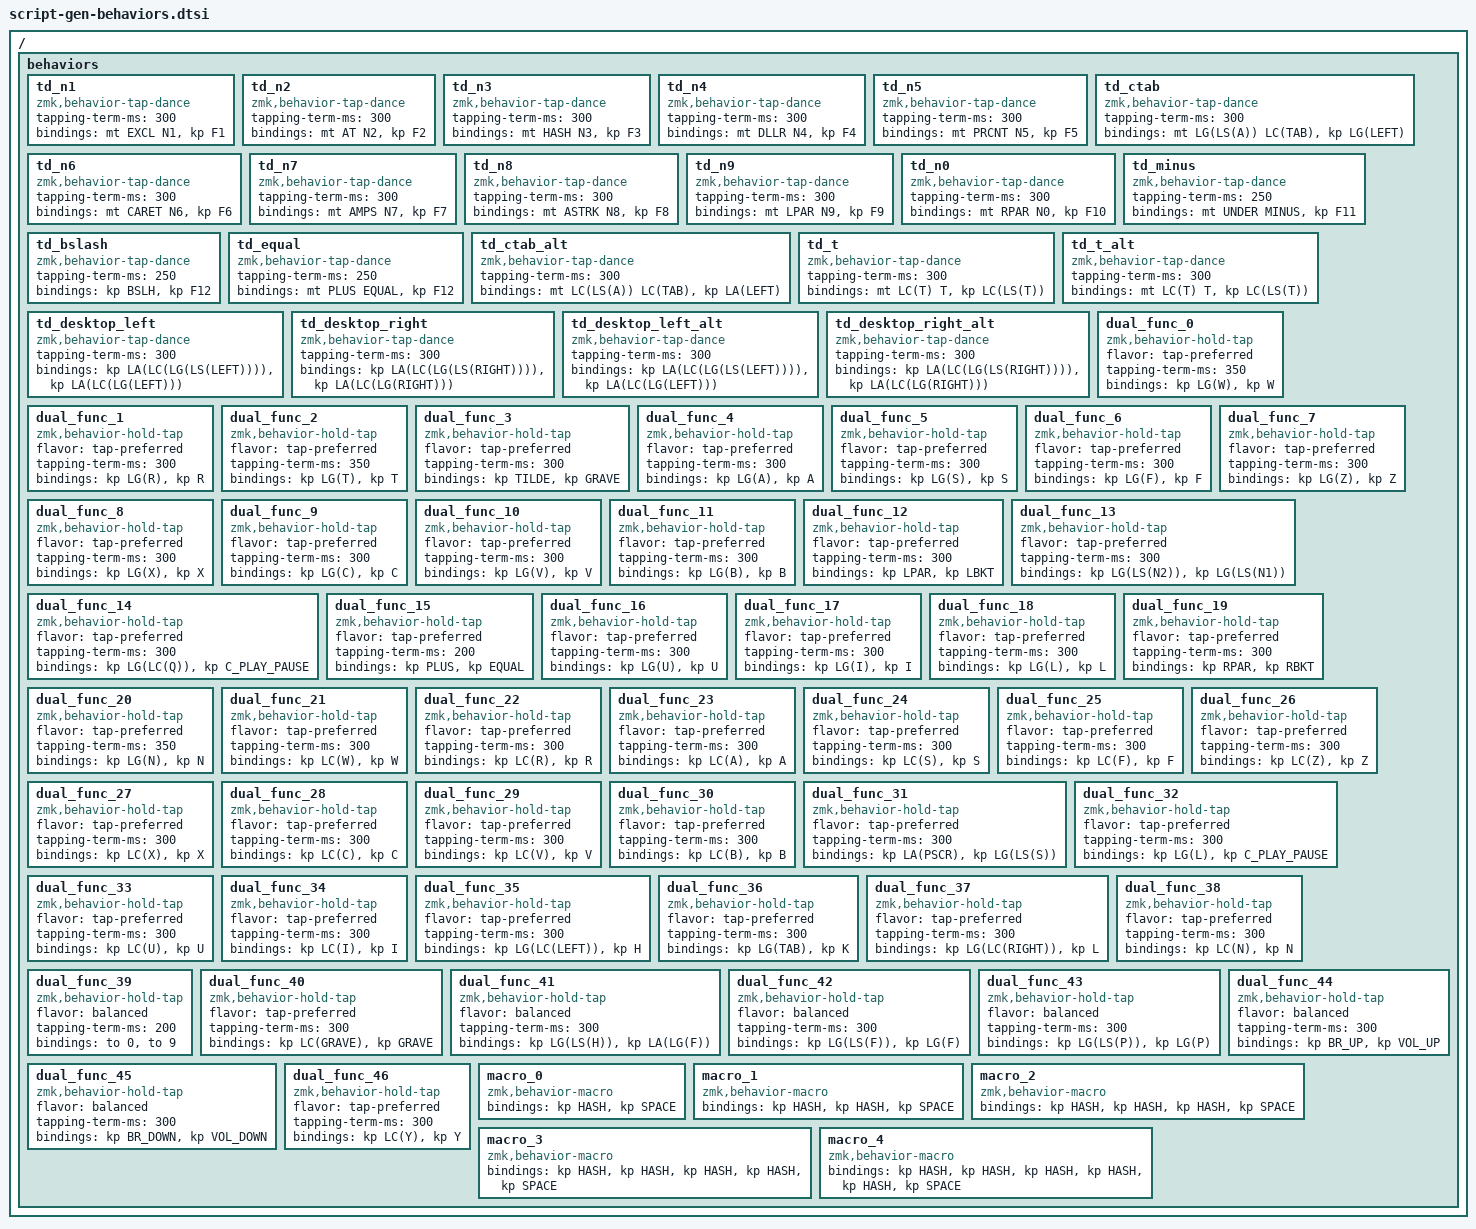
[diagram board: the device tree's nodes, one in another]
// Curated behaviors for converted Ergodox keymap (tri-function taps, dual functions, macros)
#include <dt-bindings/zmk/keys.h>

/ {
    behaviors {
        // Tri-function number row (tap=number, hold=symbol via mod-tap first binding, double-tap=Fx second binding)
        td_n1: td_n1 { compatible = "zmk,behavior-tap-dance"; #binding-cells = <0>; tapping-term-ms = <300>; bindings = <&mt EXCL N1>, <&kp F1>; };
        td_n2: td_n2 { compatible = "zmk,behavior-tap-dance"; #binding-cells = <0>; tapping-term-ms = <300>; bindings = <&mt AT N2>, <&kp F2>; };
        td_n3: td_n3 { compatible = "zmk,behavior-tap-dance"; #binding-cells = <0>; tapping-term-ms = <300>; bindings = <&mt HASH N3>, <&kp F3>; };
        td_n4: td_n4 { compatible = "zmk,behavior-tap-dance"; #binding-cells = <0>; tapping-term-ms = <300>; bindings = <&mt DLLR N4>, <&kp F4>; };
        td_n5: td_n5 { compatible = "zmk,behavior-tap-dance"; #binding-cells = <0>; tapping-term-ms = <300>; bindings = <&mt PRCNT N5>, <&kp F5>; };
        td_ctab: td_ctab { compatible = "zmk,behavior-tap-dance"; #binding-cells = <0>; tapping-term-ms = <300>; bindings = <&mt LG(LS(A)) LC(TAB)>, <&kp LG(LEFT)>; };
        td_n6: td_n6 { compatible = "zmk,behavior-tap-dance"; #binding-cells = <0>; tapping-term-ms = <300>; bindings = <&mt CARET N6>, <&kp F6>; };
        td_n7: td_n7 { compatible = "zmk,behavior-tap-dance"; #binding-cells = <0>; tapping-term-ms = <300>; bindings = <&mt AMPS N7>, <&kp F7>; };
        td_n8: td_n8 { compatible = "zmk,behavior-tap-dance"; #binding-cells = <0>; tapping-term-ms = <300>; bindings = <&mt ASTRK N8>, <&kp F8>; };
        td_n9: td_n9 { compatible = "zmk,behavior-tap-dance"; #binding-cells = <0>; tapping-term-ms = <300>; bindings = <&mt LPAR N9>, <&kp F9>; };
        td_n0: td_n0 { compatible = "zmk,behavior-tap-dance"; #binding-cells = <0>; tapping-term-ms = <300>; bindings = <&mt RPAR N0>, <&kp F10>; };
        td_minus: td_minus { compatible = "zmk,behavior-tap-dance"; #binding-cells = <0>; tapping-term-ms = <250>; bindings = <&mt UNDER MINUS>, <&kp F11>; };
        td_bslash: td_bslash { compatible = "zmk,behavior-tap-dance"; #binding-cells = <0>; tapping-term-ms = <250>; bindings = <&kp BSLH>, <&kp F12>; };
        td_equal: td_equal { compatible = "zmk,behavior-tap-dance"; #binding-cells = <0>; tapping-term-ms = <250>; bindings = <&mt PLUS EQUAL>, <&kp F12>; };

        // Reused tap dances (workspace, T chord, desktop nav variants)
        td_ctab_alt: td_ctab_alt { compatible = "zmk,behavior-tap-dance"; #binding-cells = <0>; tapping-term-ms = <300>; bindings = <&mt LC(LS(A)) LC(TAB)>, <&kp LA(LEFT)>; };
        td_t: td_t { compatible = "zmk,behavior-tap-dance"; #binding-cells = <0>; tapping-term-ms = <300>; bindings = <&mt LC(T) T>, <&kp LC(LS(T))>; };
        td_t_alt: td_t_alt { compatible = "zmk,behavior-tap-dance"; #binding-cells = <0>; tapping-term-ms = <300>; bindings = <&mt LC(T) T>, <&kp LC(LS(T))>; };
        td_desktop_left: td_desktop_left { compatible = "zmk,behavior-tap-dance"; #binding-cells = <0>; tapping-term-ms = <300>; bindings = <&kp LA(LC(LG(LS(LEFT))))>, <&kp LA(LC(LG(LEFT)))>; };
        td_desktop_right: td_desktop_right { compatible = "zmk,behavior-tap-dance"; #binding-cells = <0>; tapping-term-ms = <300>; bindings = <&kp LA(LC(LG(LS(RIGHT))))>, <&kp LA(LC(LG(RIGHT)))>; };
        td_desktop_left_alt: td_desktop_left_alt { compatible = "zmk,behavior-tap-dance"; #binding-cells = <0>; tapping-term-ms = <300>; bindings = <&kp LA(LC(LG(LS(LEFT))))>, <&kp LA(LC(LG(LEFT)))>; };
        td_desktop_right_alt: td_desktop_right_alt { compatible = "zmk,behavior-tap-dance"; #binding-cells = <0>; tapping-term-ms = <300>; bindings = <&kp LA(LC(LG(LS(RIGHT))))>, <&kp LA(LC(LG(RIGHT)))>; };

        // Dual-function hold-tap keys
        dual_func_0: dual_func_0 { compatible = "zmk,behavior-hold-tap"; #binding-cells = <2>; flavor = "tap-preferred"; tapping-term-ms = <350>; bindings = <&kp LG(W)>, <&kp W>; };
        dual_func_1: dual_func_1 { compatible = "zmk,behavior-hold-tap"; #binding-cells = <2>; flavor = "tap-preferred"; tapping-term-ms = <300>; bindings = <&kp LG(R)>, <&kp R>; };
        dual_func_2: dual_func_2 { compatible = "zmk,behavior-hold-tap"; #binding-cells = <2>; flavor = "tap-preferred"; tapping-term-ms = <350>; bindings = <&kp LG(T)>, <&kp T>; };
        dual_func_3: dual_func_3 { compatible = "zmk,behavior-hold-tap"; #binding-cells = <2>; flavor = "tap-preferred"; tapping-term-ms = <300>; bindings = <&kp TILDE>, <&kp GRAVE>; };
        dual_func_4: dual_func_4 { compatible = "zmk,behavior-hold-tap"; #binding-cells = <2>; flavor = "tap-preferred"; tapping-term-ms = <300>; bindings = <&kp LG(A)>, <&kp A>; };
        dual_func_5: dual_func_5 { compatible = "zmk,behavior-hold-tap"; #binding-cells = <2>; flavor = "tap-preferred"; tapping-term-ms = <300>; bindings = <&kp LG(S)>, <&kp S>; };
        dual_func_6: dual_func_6 { compatible = "zmk,behavior-hold-tap"; #binding-cells = <2>; flavor = "tap-preferred"; tapping-term-ms = <300>; bindings = <&kp LG(F)>, <&kp F>; };
        dual_func_7: dual_func_7 { compatible = "zmk,behavior-hold-tap"; #binding-cells = <2>; flavor = "tap-preferred"; tapping-term-ms = <300>; bindings = <&kp LG(Z)>, <&kp Z>; };
        dual_func_8: dual_func_8 { compatible = "zmk,behavior-hold-tap"; #binding-cells = <2>; flavor = "tap-preferred"; tapping-term-ms = <300>; bindings = <&kp LG(X)>, <&kp X>; };
        dual_func_9: dual_func_9 { compatible = "zmk,behavior-hold-tap"; #binding-cells = <2>; flavor = "tap-preferred"; tapping-term-ms = <300>; bindings = <&kp LG(C)>, <&kp C>; };
        dual_func_10: dual_func_10 { compatible = "zmk,behavior-hold-tap"; #binding-cells = <2>; flavor = "tap-preferred"; tapping-term-ms = <300>; bindings = <&kp LG(V)>, <&kp V>; };
        dual_func_11: dual_func_11 { compatible = "zmk,behavior-hold-tap"; #binding-cells = <2>; flavor = "tap-preferred"; tapping-term-ms = <300>; bindings = <&kp LG(B)>, <&kp B>; };
        dual_func_12: dual_func_12 { compatible = "zmk,behavior-hold-tap"; #binding-cells = <2>; flavor = "tap-preferred"; tapping-term-ms = <300>; bindings = <&kp LPAR>, <&kp LBKT>; };
        dual_func_13: dual_func_13 { compatible = "zmk,behavior-hold-tap"; #binding-cells = <2>; flavor = "tap-preferred"; tapping-term-ms = <300>; bindings = <&kp LG(LS(N2))>, <&kp LG(LS(N1))>; };
        dual_func_14: dual_func_14 { compatible = "zmk,behavior-hold-tap"; #binding-cells = <2>; flavor = "tap-preferred"; tapping-term-ms = <300>; bindings = <&kp LG(LC(Q))>, <&kp C_PLAY_PAUSE>; };
        dual_func_15: dual_func_15 { compatible = "zmk,behavior-hold-tap"; #binding-cells = <2>; flavor = "tap-preferred"; tapping-term-ms = <200>; bindings = <&kp PLUS>, <&kp EQUAL>; };
        dual_func_16: dual_func_16 { compatible = "zmk,behavior-hold-tap"; #binding-cells = <2>; flavor = "tap-preferred"; tapping-term-ms = <300>; bindings = <&kp LG(U)>, <&kp U>; };
        dual_func_17: dual_func_17 { compatible = "zmk,behavior-hold-tap"; #binding-cells = <2>; flavor = "tap-preferred"; tapping-term-ms = <300>; bindings = <&kp LG(I)>, <&kp I>; };
        dual_func_18: dual_func_18 { compatible = "zmk,behavior-hold-tap"; #binding-cells = <2>; flavor = "tap-preferred"; tapping-term-ms = <300>; bindings = <&kp LG(L)>, <&kp L>; };
        dual_func_19: dual_func_19 { compatible = "zmk,behavior-hold-tap"; #binding-cells = <2>; flavor = "tap-preferred"; tapping-term-ms = <300>; bindings = <&kp RPAR>, <&kp RBKT>; };
        dual_func_20: dual_func_20 { compatible = "zmk,behavior-hold-tap"; #binding-cells = <2>; flavor = "tap-preferred"; tapping-term-ms = <350>; bindings = <&kp LG(N)>, <&kp N>; };
        dual_func_21: dual_func_21 { compatible = "zmk,behavior-hold-tap"; #binding-cells = <2>; flavor = "tap-preferred"; tapping-term-ms = <300>; bindings = <&kp LC(W)>, <&kp W>; };
        dual_func_22: dual_func_22 { compatible = "zmk,behavior-hold-tap"; #binding-cells = <2>; flavor = "tap-preferred"; tapping-term-ms = <300>; bindings = <&kp LC(R)>, <&kp R>; };
        dual_func_23: dual_func_23 { compatible = "zmk,behavior-hold-tap"; #binding-cells = <2>; flavor = "tap-preferred"; tapping-term-ms = <300>; bindings = <&kp LC(A)>, <&kp A>; };
        dual_func_24: dual_func_24 { compatible = "zmk,behavior-hold-tap"; #binding-cells = <2>; flavor = "tap-preferred"; tapping-term-ms = <300>; bindings = <&kp LC(S)>, <&kp S>; };
        dual_func_25: dual_func_25 { compatible = "zmk,behavior-hold-tap"; #binding-cells = <2>; flavor = "tap-preferred"; tapping-term-ms = <300>; bindings = <&kp LC(F)>, <&kp F>; };
        dual_func_26: dual_func_26 { compatible = "zmk,behavior-hold-tap"; #binding-cells = <2>; flavor = "tap-preferred"; tapping-term-ms = <300>; bindings = <&kp LC(Z)>, <&kp Z>; };
        dual_func_27: dual_func_27 { compatible = "zmk,behavior-hold-tap"; #binding-cells = <2>; flavor = "tap-preferred"; tapping-term-ms = <300>; bindings = <&kp LC(X)>, <&kp X>; };
        dual_func_28: dual_func_28 { compatible = "zmk,behavior-hold-tap"; #binding-cells = <2>; flavor = "tap-preferred"; tapping-term-ms = <300>; bindings = <&kp LC(C)>, <&kp C>; };
        dual_func_29: dual_func_29 { compatible = "zmk,behavior-hold-tap"; #binding-cells = <2>; flavor = "tap-preferred"; tapping-term-ms = <300>; bindings = <&kp LC(V)>, <&kp V>; };
        dual_func_30: dual_func_30 { compatible = "zmk,behavior-hold-tap"; #binding-cells = <2>; flavor = "tap-preferred"; tapping-term-ms = <300>; bindings = <&kp LC(B)>, <&kp B>; };
        dual_func_31: dual_func_31 { compatible = "zmk,behavior-hold-tap"; #binding-cells = <2>; flavor = "tap-preferred"; tapping-term-ms = <300>; bindings = <&kp LA(PSCR)>, <&kp LG(LS(S))>; };
        dual_func_32: dual_func_32 { compatible = "zmk,behavior-hold-tap"; #binding-cells = <2>; flavor = "tap-preferred"; tapping-term-ms = <300>; bindings = <&kp LG(L)>, <&kp C_PLAY_PAUSE>; };
        dual_func_33: dual_func_33 { compatible = "zmk,behavior-hold-tap"; #binding-cells = <2>; flavor = "tap-preferred"; tapping-term-ms = <300>; bindings = <&kp LC(U)>, <&kp U>; };
        dual_func_34: dual_func_34 { compatible = "zmk,behavior-hold-tap"; #binding-cells = <2>; flavor = "tap-preferred"; tapping-term-ms = <300>; bindings = <&kp LC(I)>, <&kp I>; };
        dual_func_35: dual_func_35 { compatible = "zmk,behavior-hold-tap"; #binding-cells = <2>; flavor = "tap-preferred"; tapping-term-ms = <300>; bindings = <&kp LG(LC(LEFT))>, <&kp H>; };
        dual_func_36: dual_func_36 { compatible = "zmk,behavior-hold-tap"; #binding-cells = <2>; flavor = "tap-preferred"; tapping-term-ms = <300>; bindings = <&kp LG(TAB)>, <&kp K>; };
        dual_func_37: dual_func_37 { compatible = "zmk,behavior-hold-tap"; #binding-cells = <2>; flavor = "tap-preferred"; tapping-term-ms = <300>; bindings = <&kp LG(LC(RIGHT))>, <&kp L>; };
        dual_func_38: dual_func_38 { compatible = "zmk,behavior-hold-tap"; #binding-cells = <2>; flavor = "tap-preferred"; tapping-term-ms = <300>; bindings = <&kp LC(N)>, <&kp N>; };
        dual_func_39: dual_func_39 { compatible = "zmk,behavior-hold-tap"; #binding-cells = <2>; flavor = "balanced"; tapping-term-ms = <200>; bindings = <&to 0>, <&to 9>; };
        dual_func_40: dual_func_40 { compatible = "zmk,behavior-hold-tap"; #binding-cells = <2>; flavor = "tap-preferred"; tapping-term-ms = <300>; bindings = <&kp LC(GRAVE)>, <&kp GRAVE>; };
        dual_func_41: dual_func_41 { compatible = "zmk,behavior-hold-tap"; #binding-cells = <2>; flavor = "balanced"; tapping-term-ms = <300>; bindings = <&kp LG(LS(H))>, <&kp LA(LG(F))>; };
        dual_func_42: dual_func_42 { compatible = "zmk,behavior-hold-tap"; #binding-cells = <2>; flavor = "balanced"; tapping-term-ms = <300>; bindings = <&kp LG(LS(F))>, <&kp LG(F)>; };
        dual_func_43: dual_func_43 { compatible = "zmk,behavior-hold-tap"; #binding-cells = <2>; flavor = "balanced"; tapping-term-ms = <300>; bindings = <&kp LG(LS(P))>, <&kp LG(P)>; };
        dual_func_44: dual_func_44 { compatible = "zmk,behavior-hold-tap"; #binding-cells = <2>; flavor = "balanced"; tapping-term-ms = <300>; bindings = <&kp BR_UP>, <&kp VOL_UP>; };
        dual_func_45: dual_func_45 { compatible = "zmk,behavior-hold-tap"; #binding-cells = <2>; flavor = "balanced"; tapping-term-ms = <300>; bindings = <&kp BR_DOWN>, <&kp VOL_DOWN>; };
        dual_func_46: dual_func_46 { compatible = "zmk,behavior-hold-tap"; #binding-cells = <2>; flavor = "tap-preferred"; tapping-term-ms = <300>; bindings = <&kp LC(Y)>, <&kp Y>; };

        // Macros replicating ST_MACRO_0..4 (Hash repeated n times + space)
        macro_0: macro_0 { compatible = "zmk,behavior-macro"; #binding-cells = <0>; bindings = <&kp HASH>, <&kp SPACE>; };
        macro_1: macro_1 { compatible = "zmk,behavior-macro"; #binding-cells = <0>; bindings = <&kp HASH>, <&kp HASH>, <&kp SPACE>; };
        macro_2: macro_2 { compatible = "zmk,behavior-macro"; #binding-cells = <0>; bindings = <&kp HASH>, <&kp HASH>, <&kp HASH>, <&kp SPACE>; };
        macro_3: macro_3 { compatible = "zmk,behavior-macro"; #binding-cells = <0>; bindings = <&kp HASH>, <&kp HASH>, <&kp HASH>, <&kp HASH>, <&kp SPACE>; };
        macro_4: macro_4 { compatible = "zmk,behavior-macro"; #binding-cells = <0>; bindings = <&kp HASH>, <&kp HASH>, <&kp HASH>, <&kp HASH>, <&kp HASH>, <&kp SPACE>; };
    };
};
